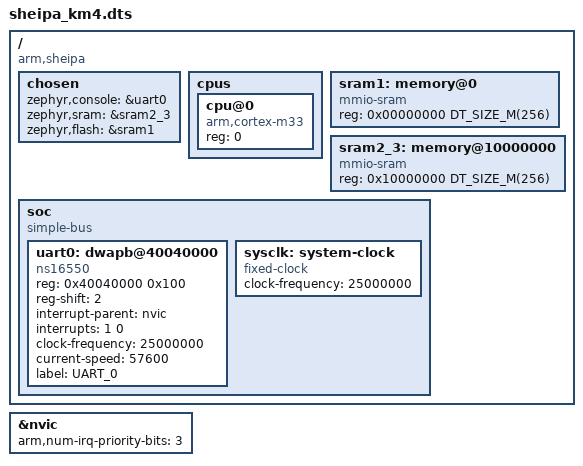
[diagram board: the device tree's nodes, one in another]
/*
 * Copyright (c) 2023 Realtek Semiconductor, Inc.
 *
 * SPDX-License-Identifier: Apache-2.0
 */

/dts-v1/;

#include <mem.h>
#include <arm/armv8-m.dtsi>

 / {
	compatible = "arm,sheipa";
	#address-cells = <1>;
	#size-cells = <1>;

	chosen {
		zephyr,console = &uart0;
		zephyr,sram = &sram2_3;
		zephyr,flash = &sram1;
	};

	cpus {
		#address-cells = <1>;
		#size-cells = <0>;

		cpu@0 {
			device_type = "cpu";
			compatible = "arm,cortex-m33";
			reg = <0>;
			#address-cells = <1>;
			#size-cells = <1>;
		};
	};

	sram1: memory@0 {
		compatible = "mmio-sram";
		reg = <0x00000000 DT_SIZE_M(256)>;
	};

	sram2_3: memory@10000000 {
		compatible = "mmio-sram";
		reg = <0x10000000 DT_SIZE_M(256)>;
	};

	soc {
		#address-cells = <1>;
		#size-cells = <1>;
		compatible = "simple-bus";

		uart0: dwapb@40040000 {
			compatible = "ns16550";
			reg = <0x40040000 0x100>;
			reg-shift = <2>;
			interrupt-parent = <&nvic>;
			interrupts = <1 0>;
			clock-frequency = <25000000>;
			current-speed = <57600>;
			label = "UART_0";
			status = "okay";
		};

		sysclk: system-clock {
			compatible = "fixed-clock";
			clock-frequency = <25000000>;
			#clock-cells = <0>;
		};
	};
};

&nvic {
	arm,num-irq-priority-bits = <3>;
};
